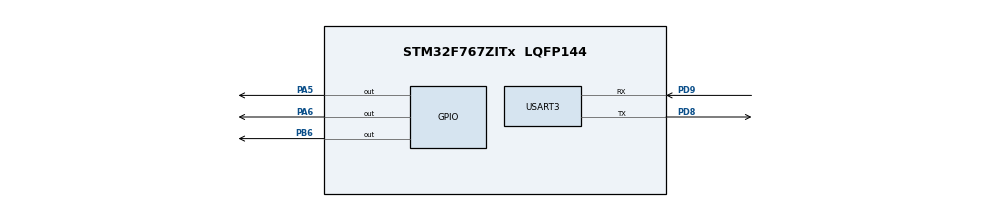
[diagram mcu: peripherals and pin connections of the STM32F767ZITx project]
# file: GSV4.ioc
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CORTEX_M7.default_mode_Activation=1
Mcu.Family=STM32F7
Mcu.Name=STM32F767ZITx
Mcu.Package=LQFP144
NVIC.PriorityGroup=NVIC_PRIORITYGROUP_4
PA5.GPIO_Speed=GPIO_SPEED_FREQ_HIGH
PA5.PinState=GPIO_PIN_SET
PA5.Signal=GPIO_Output
PA6.GPIO_Speed=GPIO_SPEED_FREQ_HIGH
PA6.PinState=GPIO_PIN_SET
PA6.Signal=GPIO_Output
PB6.GPIO_Speed=GPIO_SPEED_FREQ_HIGH
PB6.PinState=GPIO_PIN_SET
PB6.Signal=GPIO_Output
PD8.Mode=Asynchronous
PD8.Signal=USART3_TX
PD9.Mode=Asynchronous
PD9.Signal=USART3_RX
PH0/OSC_IN.Mode=HSE-External-Oscillator
PH0/OSC_IN.Signal=RCC_OSC_IN
PH1/OSC_OUT.Mode=HSE-External-Oscillator
PH1/OSC_OUT.Signal=RCC_OSC_OUT
ProjectManager.HeapSize=0x200
ProjectManager.StackSize=0x400
ProjectManager.TargetToolchain=EWARM V8.50
RCC.HSE_VALUE=25000000
RCC.HSI_VALUE=16000000
RCC.LSE_VALUE=32768
RCC.USBFreq_Value=96000000
RCC.VCOOutputFreq_Value=192000000
USART3.VirtualMode-Asynchronous=VM_ASYNC
board=custom

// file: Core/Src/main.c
/* USER CODE BEGIN Header */
/**
  ******************************************************************************
  * @file           : main.c
  * @brief          : Main program body
  ******************************************************************************
  * @attention
  *
  * Copyright (c) 2026 STMicroelectronics.
  * All rights reserved.
  *
  * This software is licensed under terms that can be found in the LICENSE file
  * in the root directory of this software component.
  * If no LICENSE file comes with this software, it is provided AS-IS.
  *
  ******************************************************************************
  */
/* USER CODE END Header */
#include "main.h"
#include<stdio.h>

UART_HandleTypeDef huart3;

void SystemClock_Config(void);
static void MPU_Config(void);
static void MX_GPIO_Init(void);
static void MX_USART3_UART_Init(void);

/* USER CODE BEGIN 0 */
int _write(int file, char *ptr, int len)
{
    HAL_UART_Transmit(&huart3,
                      (uint8_t *)ptr,
                      len,
                      HAL_MAX_DELAY);

    return len;
}
/* USER CODE END 0 */

int main(void)
{

  /* MPU Configuration--------------------------------------------------------*/
  MPU_Config();

  /* MCU Configuration--------------------------------------------------------*/

  /* Reset of all peripherals, Initializes the Flash interface and the Systick. */
  HAL_Init();

  /* Configure the system clock */
  SystemClock_Config();

  /* Initialize all configured peripherals */
  MX_GPIO_Init();
  MX_USART3_UART_Init();
  /* USER CODE BEGIN 2 */
  printf("\r\n");
  printf("===============================\r\n");
  printf("TLI5012B TEST\r\n");
  printf("STM32F767\r\n");
  printf("UART3 OK\r\n");
  printf("===============================\r\n");
  /* USER CODE END 2 */

  /* Infinite loop */
  while (1)
  {

    /* USER CODE BEGIN 3 */
	  printf("STM32 Running\r\n");

	  HAL_Delay(1000);
  }
  /* USER CODE END 3 */
}

void SystemClock_Config(void)
{
  RCC_OscInitTypeDef RCC_OscInitStruct = {0};
  RCC_ClkInitTypeDef RCC_ClkInitStruct = {0};

  /** Configure the main internal regulator output voltage
  */
  __HAL_RCC_PWR_CLK_ENABLE();
  __HAL_PWR_VOLTAGESCALING_CONFIG(PWR_REGULATOR_VOLTAGE_SCALE3);

  /** Initializes the RCC Oscillators according to the specified parameters
  * in the RCC_OscInitTypeDef structure.
  */
  RCC_OscInitStruct.OscillatorType = RCC_OSCILLATORTYPE_HSI;
  RCC_OscInitStruct.HSIState = RCC_HSI_ON;
  RCC_OscInitStruct.HSICalibrationValue = RCC_HSICALIBRATION_DEFAULT;
  RCC_OscInitStruct.PLL.PLLState = RCC_PLL_NONE;
  if (HAL_RCC_OscConfig(&RCC_OscInitStruct) != HAL_OK)
  {
    Error_Handler();
  }

  /** Initializes the CPU, AHB and APB buses clocks
  */
  RCC_ClkInitStruct.ClockType = RCC_CLOCKTYPE_HCLK|RCC_CLOCKTYPE_SYSCLK
                              |RCC_CLOCKTYPE_PCLK1|RCC_CLOCKTYPE_PCLK2;
  RCC_ClkInitStruct.SYSCLKSource = RCC_SYSCLKSOURCE_HSI;
  RCC_ClkInitStruct.AHBCLKDivider = RCC_SYSCLK_DIV1;
  RCC_ClkInitStruct.APB1CLKDivider = RCC_HCLK_DIV1;
  RCC_ClkInitStruct.APB2CLKDivider = RCC_HCLK_DIV1;

  if (HAL_RCC_ClockConfig(&RCC_ClkInitStruct, FLASH_LATENCY_0) != HAL_OK)
  {
    Error_Handler();
  }
}

static void MX_USART3_UART_Init(void)
{

  huart3.Instance = USART3;
  huart3.Init.BaudRate = 115200;
  huart3.Init.WordLength = UART_WORDLENGTH_8B;
  huart3.Init.StopBits = UART_STOPBITS_1;
  huart3.Init.Parity = UART_PARITY_NONE;
  huart3.Init.Mode = UART_MODE_TX_RX;
  huart3.Init.HwFlowCtl = UART_HWCONTROL_NONE;
  huart3.Init.OverSampling = UART_OVERSAMPLING_16;
  huart3.Init.OneBitSampling = UART_ONE_BIT_SAMPLE_DISABLE;
  huart3.AdvancedInit.AdvFeatureInit = UART_ADVFEATURE_NO_INIT;
  if (HAL_UART_Init(&huart3) != HAL_OK)
  {
    Error_Handler();
  }

}

static void MX_GPIO_Init(void)
{
  GPIO_InitTypeDef GPIO_InitStruct = {0};

  /* GPIO Ports Clock Enable */
  __HAL_RCC_GPIOH_CLK_ENABLE();
  __HAL_RCC_GPIOA_CLK_ENABLE();
  __HAL_RCC_GPIOD_CLK_ENABLE();
  __HAL_RCC_GPIOB_CLK_ENABLE();

  /*Configure GPIO pin Output Level */
  HAL_GPIO_WritePin(GPIOA, GPIO_PIN_5|GPIO_PIN_6, GPIO_PIN_SET);

  /*Configure GPIO pin Output Level */
  HAL_GPIO_WritePin(GPIOB, GPIO_PIN_6, GPIO_PIN_SET);

  /*Configure GPIO pins : PA5 PA6 */
  GPIO_InitStruct.Pin = GPIO_PIN_5|GPIO_PIN_6;
  GPIO_InitStruct.Mode = GPIO_MODE_OUTPUT_PP;
  GPIO_InitStruct.Pull = GPIO_NOPULL;
  GPIO_InitStruct.Speed = GPIO_SPEED_FREQ_HIGH;
  HAL_GPIO_Init(GPIOA, &GPIO_InitStruct);

  /*Configure GPIO pin : PB6 */
  GPIO_InitStruct.Pin = GPIO_PIN_6;
  GPIO_InitStruct.Mode = GPIO_MODE_OUTPUT_PP;
  GPIO_InitStruct.Pull = GPIO_NOPULL;
  GPIO_InitStruct.Speed = GPIO_SPEED_FREQ_HIGH;
  HAL_GPIO_Init(GPIOB, &GPIO_InitStruct);

}

 /* MPU Configuration */

void MPU_Config(void)
{
  MPU_Region_InitTypeDef MPU_InitStruct = {0};

  /* Disables the MPU */
  HAL_MPU_Disable();

  /** Initializes and configures the Region and the memory to be protected
  */
  MPU_InitStruct.Enable = MPU_REGION_ENABLE;
  MPU_InitStruct.Number = MPU_REGION_NUMBER0;
  MPU_InitStruct.BaseAddress = 0x0;
  MPU_InitStruct.Size = MPU_REGION_SIZE_4GB;
  MPU_InitStruct.SubRegionDisable = 0x87;
  MPU_InitStruct.TypeExtField = MPU_TEX_LEVEL0;
  MPU_InitStruct.AccessPermission = MPU_REGION_NO_ACCESS;
  MPU_InitStruct.DisableExec = MPU_INSTRUCTION_ACCESS_DISABLE;
  MPU_InitStruct.IsShareable = MPU_ACCESS_SHAREABLE;
  MPU_InitStruct.IsCacheable = MPU_ACCESS_NOT_CACHEABLE;
  MPU_InitStruct.IsBufferable = MPU_ACCESS_NOT_BUFFERABLE;

  HAL_MPU_ConfigRegion(&MPU_InitStruct);
  /* Enables the MPU */
  HAL_MPU_Enable(MPU_PRIVILEGED_DEFAULT);

}

void Error_Handler(void)
{
  __disable_irq();
  while (1)
  {
  }
}
